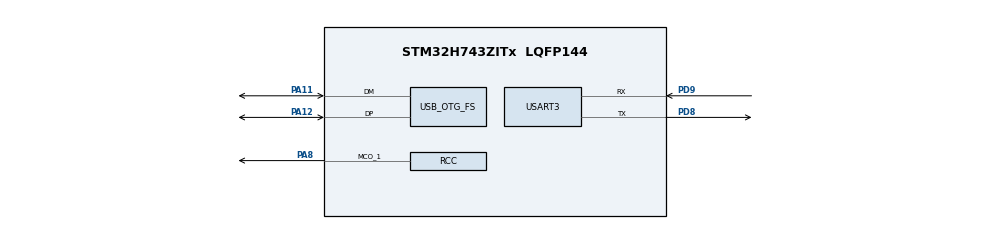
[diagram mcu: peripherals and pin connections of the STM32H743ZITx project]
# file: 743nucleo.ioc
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CORTEX_M7.AccessPermission-Cortex_Memory_Protection_Unit_Region0_Settings=MPU_REGION_PRIV_RO_URO
CORTEX_M7.AccessPermission-Cortex_Memory_Protection_Unit_Region1_Settings=MPU_REGION_FULL_ACCESS
CORTEX_M7.AccessPermission-Cortex_Memory_Protection_Unit_Region2_Settings=MPU_REGION_FULL_ACCESS
CORTEX_M7.AccessPermission-Cortex_Memory_Protection_Unit_Region3_Settings=MPU_REGION_FULL_ACCESS
CORTEX_M7.AccessPermission-Cortex_Memory_Protection_Unit_Region4_Settings=MPU_REGION_FULL_ACCESS
CORTEX_M7.AccessPermission-Cortex_Memory_Protection_Unit_Region5_Settings=MPU_REGION_FULL_ACCESS
CORTEX_M7.BaseAddress-Cortex_Memory_Protection_Unit_Region0_Settings=0x08000000
CORTEX_M7.BaseAddress-Cortex_Memory_Protection_Unit_Region1_Settings=0x24000000
CORTEX_M7.BaseAddress-Cortex_Memory_Protection_Unit_Region2_Settings=0x30000000
CORTEX_M7.BaseAddress-Cortex_Memory_Protection_Unit_Region3_Settings=0x30020000
CORTEX_M7.BaseAddress-Cortex_Memory_Protection_Unit_Region4_Settings=0x30040000
CORTEX_M7.BaseAddress-Cortex_Memory_Protection_Unit_Region5_Settings=0x38000000
CORTEX_M7.BaseAddress-Cortex_Memory_Protection_Unit_Region6_Settings=0x38800000
CORTEX_M7.CPU_DCache=Enabled
CORTEX_M7.CPU_ICache=Enabled
CORTEX_M7.Enable-Cortex_Memory_Protection_Unit_Region0_Settings=MPU_REGION_ENABLE
CORTEX_M7.Enable-Cortex_Memory_Protection_Unit_Region1_Settings=MPU_REGION_ENABLE
CORTEX_M7.Enable-Cortex_Memory_Protection_Unit_Region2_Settings=MPU_REGION_ENABLE
CORTEX_M7.Enable-Cortex_Memory_Protection_Unit_Region3_Settings=MPU_REGION_ENABLE
CORTEX_M7.Enable-Cortex_Memory_Protection_Unit_Region4_Settings=MPU_REGION_ENABLE
CORTEX_M7.Enable-Cortex_Memory_Protection_Unit_Region5_Settings=MPU_REGION_ENABLE
CORTEX_M7.Enable-Cortex_Memory_Protection_Unit_Region6_Settings=MPU_REGION_ENABLE
CORTEX_M7.IsBufferable-Cortex_Memory_Protection_Unit_Region1_Settings=MPU_ACCESS_NOT_BUFFERABLE
CORTEX_M7.IsCacheable-Cortex_Memory_Protection_Unit_Region0_Settings=MPU_ACCESS_CACHEABLE
CORTEX_M7.IsCacheable-Cortex_Memory_Protection_Unit_Region1_Settings=MPU_ACCESS_CACHEABLE
CORTEX_M7.IsCacheable-Cortex_Memory_Protection_Unit_Region2_Settings=MPU_ACCESS_CACHEABLE
CORTEX_M7.IsCacheable-Cortex_Memory_Protection_Unit_Region3_Settings=MPU_ACCESS_CACHEABLE
CORTEX_M7.IsCacheable-Cortex_Memory_Protection_Unit_Region4_Settings=MPU_ACCESS_CACHEABLE
CORTEX_M7.IsCacheable-Cortex_Memory_Protection_Unit_Region5_Settings=MPU_ACCESS_CACHEABLE
CORTEX_M7.IsCacheable-Cortex_Memory_Protection_Unit_Region6_Settings=MPU_ACCESS_CACHEABLE
CORTEX_M7.IsShareable-Cortex_Memory_Protection_Unit_Region0_Settings=MPU_ACCESS_SHAREABLE
CORTEX_M7.IsShareable-Cortex_Memory_Protection_Unit_Region1_Settings=MPU_ACCESS_SHAREABLE
CORTEX_M7.IsShareable-Cortex_Memory_Protection_Unit_Region2_Settings=MPU_ACCESS_SHAREABLE
CORTEX_M7.IsShareable-Cortex_Memory_Protection_Unit_Region3_Settings=MPU_ACCESS_SHAREABLE
CORTEX_M7.IsShareable-Cortex_Memory_Protection_Unit_Region4_Settings=MPU_ACCESS_SHAREABLE
CORTEX_M7.IsShareable-Cortex_Memory_Protection_Unit_Region5_Settings=MPU_ACCESS_SHAREABLE
CORTEX_M7.IsShareable-Cortex_Memory_Protection_Unit_Region6_Settings=MPU_ACCESS_SHAREABLE
CORTEX_M7.MPU_Control=MPU_PRIVILEGED_DEFAULT
CORTEX_M7.Size-Cortex_Memory_Protection_Unit_Region0_Settings=MPU_REGION_SIZE_2MB
CORTEX_M7.Size-Cortex_Memory_Protection_Unit_Region1_Settings=MPU_REGION_SIZE_512KB
CORTEX_M7.Size-Cortex_Memory_Protection_Unit_Region2_Settings=MPU_REGION_SIZE_128KB
CORTEX_M7.Size-Cortex_Memory_Protection_Unit_Region3_Settings=MPU_REGION_SIZE_128KB
CORTEX_M7.Size-Cortex_Memory_Protection_Unit_Region4_Settings=MPU_REGION_SIZE_32KB
CORTEX_M7.Size-Cortex_Memory_Protection_Unit_Region5_Settings=MPU_REGION_SIZE_64KB
CORTEX_M7.Size-Cortex_Memory_Protection_Unit_Region6_Settings=MPU_REGION_SIZE_4KB
Dma.Request0=USART3_RX
Dma.Request1=USART3_TX
Dma.USART3_RX.0.Direction=DMA_PERIPH_TO_MEMORY
Dma.USART3_RX.0.EventEnable=DISABLE
Dma.USART3_RX.0.FIFOMode=DMA_FIFOMODE_DISABLE
Dma.USART3_RX.0.Instance=DMA1_Stream0
Dma.USART3_RX.0.MemDataAlignment=DMA_MDATAALIGN_BYTE
Dma.USART3_RX.0.MemInc=DMA_MINC_ENABLE
Dma.USART3_RX.0.Mode=DMA_NORMAL
Dma.USART3_RX.0.PeriphDataAlignment=DMA_PDATAALIGN_BYTE
Dma.USART3_RX.0.PeriphInc=DMA_PINC_DISABLE
Dma.USART3_RX.0.Polarity=HAL_DMAMUX_REQ_GEN_RISING
Dma.USART3_RX.0.Priority=DMA_PRIORITY_LOW
Dma.USART3_RX.0.RequestNumber=1
Dma.USART3_RX.0.SyncEnable=DISABLE
Dma.USART3_RX.0.SyncPolarity=HAL_DMAMUX_SYNC_NO_EVENT
Dma.USART3_RX.0.SyncRequestNumber=1
Dma.USART3_TX.1.Direction=DMA_MEMORY_TO_PERIPH
Dma.USART3_TX.1.EventEnable=DISABLE
Dma.USART3_TX.1.FIFOMode=DMA_FIFOMODE_DISABLE
Dma.USART3_TX.1.Instance=DMA1_Stream1
Dma.USART3_TX.1.MemDataAlignment=DMA_MDATAALIGN_BYTE
Dma.USART3_TX.1.MemInc=DMA_MINC_ENABLE
Dma.USART3_TX.1.Mode=DMA_NORMAL
Dma.USART3_TX.1.PeriphDataAlignment=DMA_PDATAALIGN_BYTE
Dma.USART3_TX.1.PeriphInc=DMA_PINC_DISABLE
Dma.USART3_TX.1.Polarity=HAL_DMAMUX_REQ_GEN_RISING
Dma.USART3_TX.1.Priority=DMA_PRIORITY_LOW
Dma.USART3_TX.1.RequestNumber=1
Dma.USART3_TX.1.SyncEnable=DISABLE
Dma.USART3_TX.1.SyncPolarity=HAL_DMAMUX_SYNC_NO_EVENT
Dma.USART3_TX.1.SyncRequestNumber=1
Mcu.Family=STM32H7
Mcu.Name=STM32H743ZITx
Mcu.Package=LQFP144
NVIC.DMA1_Stream0_IRQn=true\:0\:0\:false\:false\:true\:false
NVIC.DMA1_Stream1_IRQn=true\:0\:0\:false\:false\:true\:false
NVIC.OTG_FS_IRQn=true\:0\:0\:false\:false\:true\:true
NVIC.PriorityGroup=NVIC_PRIORITYGROUP_4
NVIC.USART3_IRQn=true\:0\:0\:false\:false\:true\:true
PA11.Mode=Device_Only
PA11.Signal=USB_OTG_FS_DM
PA12.Mode=Device_Only
PA12.Signal=USB_OTG_FS_DP
PA13\ (JTMS/SWDIO).Mode=Serial_Wire
PA13\ (JTMS/SWDIO).Signal=SYS_JTMS-SWDIO
PA14\ (JTCK/SWCLK).Mode=Serial_Wire
PA14\ (JTCK/SWCLK).Signal=SYS_JTCK-SWCLK
PA8.Mode=Clock-out-1
PA8.Signal=RCC_MCO_1
PC14-OSC32_IN\ (OSC32_IN).Mode=LSE-External-Clock-Source
PC14-OSC32_IN\ (OSC32_IN).Signal=RCC_OSC32_IN
PC15-OSC32_OUT\ (OSC32_OUT).Mode=LSE-External-Clock-Source
PC15-OSC32_OUT\ (OSC32_OUT).Signal=RCC_OSC32_OUT
PD8.Mode=Asynchronous
PD8.Signal=USART3_TX
PD9.Mode=Asynchronous
PD9.Signal=USART3_RX
PG11.Signal=ETH_TX_EN
PG13.Signal=ETH_TXD0
PH0-OSC_IN\ (PH0).Mode=HSE-External-Clock-Source
PH0-OSC_IN\ (PH0).Signal=RCC_OSC_IN
PH1-OSC_OUT\ (PH1).Mode=HSE-External-Clock-Source
PH1-OSC_OUT\ (PH1).Signal=RCC_OSC_OUT
ProjectManager.HeapSize=0x2000
ProjectManager.StackSize=0x4000
ProjectManager.TargetToolchain=MDK-ARM V5
RCC.ADCFreq_Value=16125000
RCC.APB1Freq_Value=100000000
RCC.APB2Freq_Value=100000000
RCC.APB3Freq_Value=100000000
RCC.APB4Freq_Value=100000000
RCC.CortexFreq_Value=400000000
RCC.D1PPRE=RCC_APB3_DIV2
RCC.D2PPRE1=RCC_APB1_DIV2
RCC.D2PPRE2=RCC_APB2_DIV2
RCC.D3PPRE=RCC_APB4_DIV2
RCC.DIVM1=1
RCC.DIVM3=1
RCC.DIVN1=100
RCC.DIVN3=96
RCC.DIVQ3=16
RCC.HCLKFreq_Value=200000000
RCC.HPRE=RCC_HCLK_DIV2
RCC.HSE_VALUE=8000000
RCC.PLLSourceVirtual=RCC_PLLSOURCE_HSE
RCC.RCC_MCO1Source=RCC_MCO1SOURCE_PLL1QCLK
RCC.RCC_MCODiv1=RCC_MCODIV_8
RCC.SYSCLKFreq_VALUE=400000000
RCC.SYSCLKSource=RCC_SYSCLKSOURCE_PLLCLK
RCC.USBCLockSelection=RCC_USBCLKSOURCE_PLL3
RCC.USBFreq_Value=48000000
USART3.VirtualMode-Asynchronous=VM_ASYNC
USB_DEVICE.CLASS_NAME_FS=CDC
USB_DEVICE.VirtualMode-CDC_FS=Cdc
USB_DEVICE.VirtualModeFS=Cdc_FS
USB_OTG_FS.VirtualMode=Device_Only
VP_USB_DEVICE_VS_USB_DEVICE_CDC_FS.Mode=CDC_FS
board=custom

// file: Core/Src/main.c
/* USER CODE BEGIN Header */
/**
  ******************************************************************************
  * @file           : main.c
  * @brief          : Main program body
  ******************************************************************************
  * This notice applies to any and all portions of this file
  * that are not between comment pairs USER CODE BEGIN and
  * USER CODE END. Other portions of this file, whether
  * inserted by the user or by software development tools
  * are owned by their respective copyright owners.
  *
  * Copyright (c) 2019 STMicroelectronics International N.V.
  * All rights reserved.
  *
  * Redistribution and use in source and binary forms, with or without
  * modification, are permitted, provided that the following conditions are met:
  *
  * 1. Redistribution of source code must retain the above copyright notice,
  *    this list of conditions and the following disclaimer.
  * 2. Redistributions in binary form must reproduce the above copyright notice,
  *    this list of conditions and the following disclaimer in the documentation
  *    and/or other materials provided with the distribution.
  * 3. Neither the name of STMicroelectronics nor the names of other
  *    contributors to this software may be used to endorse or promote products
  *    derived from this software without specific written permission.
  * 4. This software, including modifications and/or derivative works of this
  *    software, must execute solely and exclusively on microcontroller or
  *    microprocessor devices manufactured by or for STMicroelectronics.
  * 5. Redistribution and use of this software other than as permitted under
  *    this license is void and will automatically terminate your rights under
  *    this license.
  *
  * THIS SOFTWARE IS PROVIDED BY STMICROELECTRONICS AND CONTRIBUTORS "AS IS"
  * AND ANY EXPRESS, IMPLIED OR STATUTORY WARRANTIES, INCLUDING, BUT NOT
  * LIMITED TO, THE IMPLIED WARRANTIES OF MERCHANTABILITY, FITNESS FOR A
  * PARTICULAR PURPOSE AND NON-INFRINGEMENT OF THIRD PARTY INTELLECTUAL PROPERTY
  * RIGHTS ARE DISCLAIMED TO THE FULLEST EXTENT PERMITTED BY LAW. IN NO EVENT
  * SHALL STMICROELECTRONICS OR CONTRIBUTORS BE LIABLE FOR ANY DIRECT, INDIRECT,
  * INCIDENTAL, SPECIAL, EXEMPLARY, OR CONSEQUENTIAL DAMAGES (INCLUDING, BUT NOT
  * LIMITED TO, PROCUREMENT OF SUBSTITUTE GOODS OR SERVICES; LOSS OF USE, DATA,
  * OR PROFITS; OR BUSINESS INTERRUPTION) HOWEVER CAUSED AND ON ANY THEORY OF
  * LIABILITY, WHETHER IN CONTRACT, STRICT LIABILITY, OR TORT (INCLUDING
  * NEGLIGENCE OR OTHERWISE) ARISING IN ANY WAY OUT OF THE USE OF THIS SOFTWARE,
  * EVEN IF ADVISED OF THE POSSIBILITY OF SUCH DAMAGE.
  *
  ******************************************************************************
  */
/* USER CODE END Header */

#include "main.h"
#include "dma.h"
#include "usart.h"
#include "usb_device.h"
#include "gpio.h"

void SystemClock_Config(void);
static void MPU_Config(void);

int main(void)
{

  /* MPU Configuration--------------------------------------------------------*/
  MPU_Config();

  /* Enable I-Cache---------------------------------------------------------*/
  SCB_EnableICache();

  /* Enable D-Cache---------------------------------------------------------*/
  SCB_EnableDCache();

  /* MCU Configuration--------------------------------------------------------*/

  /* Reset of all peripherals, Initializes the Flash interface and the Systick. */
  HAL_Init();

  /* Configure the system clock */
  SystemClock_Config();

  /* Initialize all configured peripherals */
  MX_GPIO_Init();
  MX_DMA_Init();
  MX_USART3_UART_Init();
  MX_USB_DEVICE_Init();
  /* USER CODE BEGIN 2 */
  HAL_PWREx_EnableUSBVoltageDetector();

  /* USER CODE END 2 */

  /* Infinite loop */
  while (1)
  {

  }
}

void SystemClock_Config(void)
{
  RCC_OscInitTypeDef RCC_OscInitStruct = {0};
  RCC_ClkInitTypeDef RCC_ClkInitStruct = {0};
  RCC_PeriphCLKInitTypeDef PeriphClkInitStruct = {0};

  /**Supply configuration update enable
  */
  MODIFY_REG(PWR->CR3, PWR_CR3_SCUEN, 0);
  /**Configure the main internal regulator output voltage
  */
  __HAL_PWR_VOLTAGESCALING_CONFIG(PWR_REGULATOR_VOLTAGE_SCALE1);

  while ((PWR->D3CR & (PWR_D3CR_VOSRDY)) != PWR_D3CR_VOSRDY)
  {

  }
  /**Macro to configure the PLL clock source
  */
  __HAL_RCC_PLL_PLLSOURCE_CONFIG(RCC_PLLSOURCE_HSE);
  /**Initializes the CPU, AHB and APB busses clocks
  */
  RCC_OscInitStruct.OscillatorType = RCC_OSCILLATORTYPE_HSE;
  RCC_OscInitStruct.HSEState = RCC_HSE_BYPASS;
  RCC_OscInitStruct.PLL.PLLState = RCC_PLL_ON;
  RCC_OscInitStruct.PLL.PLLSource = RCC_PLLSOURCE_HSE;
  RCC_OscInitStruct.PLL.PLLM = 1;
  RCC_OscInitStruct.PLL.PLLN = 100;
  RCC_OscInitStruct.PLL.PLLP = 2;
  RCC_OscInitStruct.PLL.PLLQ = 2;
  RCC_OscInitStruct.PLL.PLLR = 2;
  RCC_OscInitStruct.PLL.PLLRGE = RCC_PLL1VCIRANGE_3;
  RCC_OscInitStruct.PLL.PLLVCOSEL = RCC_PLL1VCOWIDE;
  RCC_OscInitStruct.PLL.PLLFRACN = 0;
  if (HAL_RCC_OscConfig(&RCC_OscInitStruct) != HAL_OK)
  {
    Error_Handler();
  }
  /**Initializes the CPU, AHB and APB busses clocks
  */
  RCC_ClkInitStruct.ClockType = RCC_CLOCKTYPE_HCLK|RCC_CLOCKTYPE_SYSCLK
                              |RCC_CLOCKTYPE_PCLK1|RCC_CLOCKTYPE_PCLK2
                              |RCC_CLOCKTYPE_D3PCLK1|RCC_CLOCKTYPE_D1PCLK1;
  RCC_ClkInitStruct.SYSCLKSource = RCC_SYSCLKSOURCE_PLLCLK;
  RCC_ClkInitStruct.SYSCLKDivider = RCC_SYSCLK_DIV1;
  RCC_ClkInitStruct.AHBCLKDivider = RCC_HCLK_DIV2;
  RCC_ClkInitStruct.APB3CLKDivider = RCC_APB3_DIV2;
  RCC_ClkInitStruct.APB1CLKDivider = RCC_APB1_DIV2;
  RCC_ClkInitStruct.APB2CLKDivider = RCC_APB2_DIV2;
  RCC_ClkInitStruct.APB4CLKDivider = RCC_APB4_DIV2;

  if (HAL_RCC_ClockConfig(&RCC_ClkInitStruct, FLASH_LATENCY_2) != HAL_OK)
  {
    Error_Handler();
  }
  PeriphClkInitStruct.PeriphClockSelection = RCC_PERIPHCLK_USART3|RCC_PERIPHCLK_USB;
  PeriphClkInitStruct.PLL3.PLL3M = 1;
  PeriphClkInitStruct.PLL3.PLL3N = 96;
  PeriphClkInitStruct.PLL3.PLL3P = 2;
  PeriphClkInitStruct.PLL3.PLL3Q = 16;
  PeriphClkInitStruct.PLL3.PLL3R = 2;
  PeriphClkInitStruct.PLL3.PLL3RGE = RCC_PLL3VCIRANGE_3;
  PeriphClkInitStruct.PLL3.PLL3VCOSEL = RCC_PLL3VCOWIDE;
  PeriphClkInitStruct.PLL3.PLL3FRACN = 0;
  PeriphClkInitStruct.Usart234578ClockSelection = RCC_USART234578CLKSOURCE_D2PCLK1;
  PeriphClkInitStruct.UsbClockSelection = RCC_USBCLKSOURCE_PLL3;
  if (HAL_RCCEx_PeriphCLKConfig(&PeriphClkInitStruct) != HAL_OK)
  {
    Error_Handler();
  }
  HAL_RCC_MCOConfig(RCC_MCO1, RCC_MCO1SOURCE_PLL1QCLK, RCC_MCODIV_8);
}

/* MPU Configuration */

void MPU_Config(void)
{
  MPU_Region_InitTypeDef MPU_InitStruct = {0};

  /* Disables the MPU */
  HAL_MPU_Disable();
  /**Initializes and configures the Region and the memory to be protected
  */
  MPU_InitStruct.Enable = MPU_REGION_ENABLE;
  MPU_InitStruct.Number = MPU_REGION_NUMBER0;
  MPU_InitStruct.BaseAddress = 0x08000000;
  MPU_InitStruct.Size = MPU_REGION_SIZE_2MB;
  MPU_InitStruct.SubRegionDisable = 0x0;
  MPU_InitStruct.TypeExtField = MPU_TEX_LEVEL0;
  MPU_InitStruct.AccessPermission = MPU_REGION_PRIV_RO_URO;
  MPU_InitStruct.DisableExec = MPU_INSTRUCTION_ACCESS_ENABLE;
  MPU_InitStruct.IsShareable = MPU_ACCESS_SHAREABLE;
  MPU_InitStruct.IsCacheable = MPU_ACCESS_CACHEABLE;
  MPU_InitStruct.IsBufferable = MPU_ACCESS_NOT_BUFFERABLE;

  HAL_MPU_ConfigRegion(&MPU_InitStruct);
  /**Initializes and configures the Region and the memory to be protected
  */
  MPU_InitStruct.Enable = MPU_REGION_ENABLE;
  MPU_InitStruct.Number = MPU_REGION_NUMBER1;
  MPU_InitStruct.BaseAddress = 0x24000000;
  MPU_InitStruct.Size = MPU_REGION_SIZE_512KB;
  MPU_InitStruct.SubRegionDisable = 0x0;
  MPU_InitStruct.TypeExtField = MPU_TEX_LEVEL0;
  MPU_InitStruct.AccessPermission = MPU_REGION_FULL_ACCESS;
  MPU_InitStruct.DisableExec = MPU_INSTRUCTION_ACCESS_ENABLE;
  MPU_InitStruct.IsShareable = MPU_ACCESS_SHAREABLE;
  MPU_InitStruct.IsCacheable = MPU_ACCESS_CACHEABLE;
  MPU_InitStruct.IsBufferable = MPU_ACCESS_NOT_BUFFERABLE;

  HAL_MPU_ConfigRegion(&MPU_InitStruct);
  /**Initializes and configures the Region and the memory to be protected
  */
  MPU_InitStruct.Enable = MPU_REGION_ENABLE;
  MPU_InitStruct.Number = MPU_REGION_NUMBER2;
  MPU_InitStruct.BaseAddress = 0x30000000;
  MPU_InitStruct.Size = MPU_REGION_SIZE_128KB;
  MPU_InitStruct.SubRegionDisable = 0x0;
  MPU_InitStruct.TypeExtField = MPU_TEX_LEVEL0;
  MPU_InitStruct.AccessPermission = MPU_REGION_FULL_ACCESS;
  MPU_InitStruct.DisableExec = MPU_INSTRUCTION_ACCESS_ENABLE;
  MPU_InitStruct.IsShareable = MPU_ACCESS_SHAREABLE;
  MPU_InitStruct.IsCacheable = MPU_ACCESS_CACHEABLE;
  MPU_InitStruct.IsBufferable = MPU_ACCESS_NOT_BUFFERABLE;

  HAL_MPU_ConfigRegion(&MPU_InitStruct);
  /**Initializes and configures the Region and the memory to be protected
  */
  MPU_InitStruct.Enable = MPU_REGION_ENABLE;
  MPU_InitStruct.Number = MPU_REGION_NUMBER3;
  MPU_InitStruct.BaseAddress = 0x30020000;
  MPU_InitStruct.Size = MPU_REGION_SIZE_128KB;
  MPU_InitStruct.SubRegionDisable = 0x0;
  MPU_InitStruct.TypeExtField = MPU_TEX_LEVEL0;
  MPU_InitStruct.AccessPermission = MPU_REGION_FULL_ACCESS;
  MPU_InitStruct.DisableExec = MPU_INSTRUCTION_ACCESS_ENABLE;
  MPU_InitStruct.IsShareable = MPU_ACCESS_SHAREABLE;
  MPU_InitStruct.IsCacheable = MPU_ACCESS_CACHEABLE;
  MPU_InitStruct.IsBufferable = MPU_ACCESS_NOT_BUFFERABLE;

  HAL_MPU_ConfigRegion(&MPU_InitStruct);
  /**Initializes and configures the Region and the memory to be protected
  */
  MPU_InitStruct.Enable = MPU_REGION_ENABLE;
  MPU_InitStruct.Number = MPU_REGION_NUMBER4;
  MPU_InitStruct.BaseAddress = 0x30040000;
  MPU_InitStruct.Size = MPU_REGION_SIZE_32KB;
  MPU_InitStruct.SubRegionDisable = 0x0;
  MPU_InitStruct.TypeExtField = MPU_TEX_LEVEL0;
  MPU_InitStruct.AccessPermission = MPU_REGION_FULL_ACCESS;
  MPU_InitStruct.DisableExec = MPU_INSTRUCTION_ACCESS_ENABLE;
  MPU_InitStruct.IsShareable = MPU_ACCESS_SHAREABLE;
  MPU_InitStruct.IsCacheable = MPU_ACCESS_CACHEABLE;
  MPU_InitStruct.IsBufferable = MPU_ACCESS_NOT_BUFFERABLE;

  HAL_MPU_ConfigRegion(&MPU_InitStruct);
  /**Initializes and configures the Region and the memory to be protected
  */
  MPU_InitStruct.Enable = MPU_REGION_ENABLE;
  MPU_InitStruct.Number = MPU_REGION_NUMBER5;
  MPU_InitStruct.BaseAddress = 0x38000000;
  MPU_InitStruct.Size = MPU_REGION_SIZE_64KB;
  MPU_InitStruct.SubRegionDisable = 0x0;
  MPU_InitStruct.TypeExtField = MPU_TEX_LEVEL0;
  MPU_InitStruct.AccessPermission = MPU_REGION_FULL_ACCESS;
  MPU_InitStruct.DisableExec = MPU_INSTRUCTION_ACCESS_ENABLE;
  MPU_InitStruct.IsShareable = MPU_ACCESS_SHAREABLE;
  MPU_InitStruct.IsCacheable = MPU_ACCESS_CACHEABLE;
  MPU_InitStruct.IsBufferable = MPU_ACCESS_NOT_BUFFERABLE;

  HAL_MPU_ConfigRegion(&MPU_InitStruct);
  /**Initializes and configures the Region and the memory to be protected
  */
  MPU_InitStruct.Enable = MPU_REGION_ENABLE;
  MPU_InitStruct.Number = MPU_REGION_NUMBER6;
  MPU_InitStruct.BaseAddress = 0x38800000;
  MPU_InitStruct.Size = MPU_REGION_SIZE_4KB;
  MPU_InitStruct.SubRegionDisable = 0x0;
  MPU_InitStruct.TypeExtField = MPU_TEX_LEVEL0;
  MPU_InitStruct.AccessPermission = MPU_REGION_NO_ACCESS;
  MPU_InitStruct.DisableExec = MPU_INSTRUCTION_ACCESS_ENABLE;
  MPU_InitStruct.IsShareable = MPU_ACCESS_SHAREABLE;
  MPU_InitStruct.IsCacheable = MPU_ACCESS_CACHEABLE;
  MPU_InitStruct.IsBufferable = MPU_ACCESS_NOT_BUFFERABLE;

  HAL_MPU_ConfigRegion(&MPU_InitStruct);
  /* Enables the MPU */
  HAL_MPU_Enable(MPU_PRIVILEGED_DEFAULT);

}

void Error_Handler(void)
{
}

/************************ (C) COPYRIGHT STMicroelectronics *****END OF FILE****/
